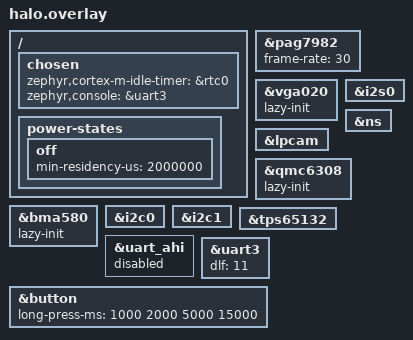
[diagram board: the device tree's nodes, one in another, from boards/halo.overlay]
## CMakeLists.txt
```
# SPDX-License-Identifier: Apache-2.0
cmake_minimum_required(VERSION 3.20.0)

# Handle RELEASE build option
# Default is debug build
# Use environment variable: RELEASE=1 west build ... for release build
set(RELEASE OFF CACHE BOOL "Enable release build")

# Check environment variable first (works with sysbuild)
if(DEFINED ENV{RELEASE} AND "$ENV{RELEASE}" STREQUAL "1")
    set(RELEASE ON)
endif()

if(RELEASE)
    message(STATUS "=== Release build enabled ===")
    set(EXTRA_CONF_FILE "release.conf" CACHE STRING "Extra config file" FORCE)
    set(BUILD_EXTRAVERSION "")
else()
    message(STATUS "=== Debug build enabled (default) ===")
    set(EXTRA_CONF_FILE "debug.conf" CACHE STRING "Extra config file" FORCE)
    set(BUILD_EXTRAVERSION "debug")
endif()

# DIAG=1: the bring-up experiment build (diag.conf: /lfs/diag.txt event log and
# the staged boot). Tagged in the version string so it can't pass for a release.
if(DEFINED ENV{DIAG} AND "$ENV{DIAG}" STREQUAL "1")
    message(STATUS "=== Diagnostic (staged boot) build ===")
    set(EXTRA_CONF_FILE "${EXTRA_CONF_FILE};diag.conf" CACHE STRING "Extra config file" FORCE)
    if(BUILD_EXTRAVERSION STREQUAL "")
        set(BUILD_EXTRAVERSION "diag")
    else()
        set(BUILD_EXTRAVERSION "${BUILD_EXTRAVERSION}diag")
    endif()
endif()

# Update VERSION file with correct EXTRAVERSION
file(READ "${CMAKE_CURRENT_SOURCE_DIR}/VERSION" VERSION_CONTENT)
string(REGEX REPLACE "EXTRAVERSION = [^\n]*" "EXTRAVERSION = ${BUILD_EXTRAVERSION}" VERSION_CONTENT "${VERSION_CONTENT}")
file(WRITE "${CMAKE_CURRENT_SOURCE_DIR}/VERSION" "${VERSION_CONTENT}")

if(SYSBUILD)
    list(APPEND EXTRA_CONF_FILE "prj_sysbuild.conf")
endif()

find_package(Zephyr REQUIRED HINTS $ENV{ZEPHYR_BASE})

project(halo)

include_directories("include")

file(GLOB_RECURSE SRC_FILES "src/*.c")
target_sources(app PRIVATE ${SRC_FILES})

libmpix_init(app)
```

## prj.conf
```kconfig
# Zephyr Project Configuration File

# Zephyr Base Configuration
CONFIG_ASSERT=y
CONFIG_LOG=y
CONFIG_LOG_DEFAULT_LEVEL=2
CONFIG_LOG_BUFFER_SIZE=8192
CONFIG_LOG_PROCESS_THREAD_CUSTOM_PRIORITY=y
CONFIG_LOG_PROCESS_THREAD_PRIORITY=3
CONFIG_LOG_PROCESS_THREAD_STACK_SIZE=2048

# Log Filesystem Backend — persist logs to LittleFS. DISABLED on this
# branch: littlefs writes hit the same flash the code executes from, so
# every persisted log line (e.g. the AEC's 10-s load INF) stalls the
# whole system mid-audio-session — the same mechanism as the /lfs
# capture-write emission gaps the AEC harnesses had to design around.
# Also returns the 2x16KB log files to /lfs. Re-enable when the audio
# timing work no longer needs stall-free sessions (the `logs` skill
# depends on it for post-flash diagnostics; `verify.py` still covers
# boot checks).
CONFIG_LOG_BACKEND_FS=n
# CONFIG_LOG_BACKEND_FS_DIR="/lfs"
# CONFIG_LOG_BACKEND_FS_AUTOSTART=y
# CONFIG_LOG_BACKEND_FS_OVERWRITE=y
# CONFIG_LOG_BACKEND_FS_FILE_PREFIX="log."
# CONFIG_LOG_BACKEND_FS_FILE_SIZE=16384
# CONFIG_LOG_BACKEND_FS_FILES_LIMIT=2

# System Workqueue Configuration
CONFIG_MAIN_STACK_SIZE=4096
CONFIG_ISR_STACK_SIZE=4096
CONFIG_PRIVILEGED_STACK_SIZE=2048
CONFIG_IDLE_STACK_SIZE=2048
CONFIG_SYSTEM_WORKQUEUE_STACK_SIZE=4096

# Power Management Configuration
CONFIG_PM=y
CONFIG_PM_DEVICE=y

# Thread Monitoring and Debugging
CONFIG_THREAD_NAME=y
CONFIG_THREAD_MONITOR=y
CONFIG_THREAD_STACK_INFO=y
CONFIG_THREAD_RUNTIME_STATS=y

# Round-robin equal-priority threads at priority 7 and below in 5 ms slices.
# The Lua REPL and the camera capture thread share priority 7: without
# slicing, a capture's ~0.5 s debayer/JPEG pass held the CPU and froze the
# Lua loop (stalling e.g. the mic stream it sends) until the image was ready.
CONFIG_TIMESLICE_SIZE=5
CONFIG_TIMESLICE_PRIORITY=7


# Halo Framework
CONFIG_HALO=y
# Acoustic echo cancellation (speaker leakage removed from the mic path)
CONFIG_HALO_AUDIO_AEC=y
CONFIG_HALO_AUDIO_AEC_TAPS=1024
CONFIG_MPIX_LOG_LEVEL_WRN=y
CONFIG_FS_LOG_LEVEL_WRN=y

# Memory Manager Configuration
# The libc malloc arena defaults to "all RAM left after static allocations",
# which had decayed to ~50 bytes - any .bss growth then fails the sys_heap
# minimum-size assert in malloc_prepare() and the image panics at boot.
# Pin the arena explicitly and give back one page from the internal pool so
# the link keeps real headroom.
CONFIG_COMMON_LIBC_MALLOC_ARENA_SIZE=2048
# (also funds the AEC's 256ms reference ring and its ~3.3KB paired-capture
# snapshot buffers - see audio_aec.c)
CONFIG_HALO_MEM_INTERNAL_SIZE=352256
CONFIG_HALO_MEM_USE_EXTERNAL_SRAM=y
CONFIG_HALO_MEM_EXTERNAL_SRAM_ADDR=0x00000000
# The first 64KB of ITCM belong to the AEC FDAF state (the linker's ITCM
# section; BUILD_ASSERTed in audio_aec.c to fit below this offset) - the
# region-1 heap starts above it. Was offset 4096 (NULL guard) + 520192.
CONFIG_HALO_MEM_EXTERNAL_SRAM_OFFSET=65536
CONFIG_HALO_MEM_EXTERNAL_SRAM_SIZE=458752
CONFIG_HALO_MEM_MANAGER_STATS=y

# Flash and Storage Configuration
CONFIG_FLASH=y
CONFIG_FLASH_MAP=y
CONFIG_FLASH_PAGE_LAYOUT=y
CONFIG_MPU_ALLOW_FLASH_WRITE=y

# LittleFS Configuration
CONFIG_FILE_SYSTEM_LITTLEFS=y
CONFIG_FS_LITTLEFS_FMP_DEV=y

# Settings Configuration
CONFIG_SETTINGS=y
CONFIG_SETTINGS_FILE=y
CONFIG_SETTINGS_FILE_PATH="/lfs/settings"

# Sensor Configuration for Battery Service
CONFIG_SENSOR=y
CONFIG_SENSOR_INIT_PRIORITY=60

# Regulator Init Priority
# cam_1v8 (regulator-fixed, priority 32) must initialize before tps65132
# (REGULATOR_TPS65132_COMMON_INIT_PRIORITY=61), since tps65132 has
# vin-supply = <&cam_1v8> and checks device_is_ready() during init.
CONFIG_REGULATOR_FIXED_INIT_PRIORITY=32
# The camera reset release (camera_boot.c, 60) sits between the camera
# driver (VIDEO_INIT_PRIORITY) and the tps65132 regulator (61), so the
# camera driver moves one ahead.
CONFIG_VIDEO_INIT_PRIORITY=59
# The camera controller's pin control muxes the sensor clock pad; it must run
# before the reset release switches that clock on.
CONFIG_VIDEO_ALIF_CAM_INIT_PRIORITY=59

# LED Configuration for Battery Charging Indicator
CONFIG_PWM=y
CONFIG_LED_PWM=y

# Halo BLE Manager Configuration
CONFIG_HALO_BLE_MAX_SERVICES=8
CONFIG_HALO_BLE_BOND_STORAGE=y
CONFIG_HALO_BLE_REQUIRE_PAIRING=y
CONFIG_HALO_BLE_ALLOW_BOND_OVERWRITE=n


# BLE Lua Service Configuration
CONFIG_HALO_BLE_LUA_SERVICE=y
CONFIG_HALO_LUA_MAX_REPL_SIZE=1024
CONFIG_HALO_LUA_MAX_DATA_SIZE=4096
CONFIG_HALO_AUDIO_MAX_DATA_SIZE=8192
CONFIG_HALO_SFXR=y
CONFIG_HALO_LUA_SOUND=y
CONFIG_HALO_STARTUP_SOUND=y
CONFIG_HALO_STARTUP_SOUND_PRESET="powerup"
CONFIG_HALO_STARTUP_SOUND_SEED=4149902225
CONFIG_HALO_STARTUP_SOUND_DURATION_MS=1000
# Boot/shutdown cues play at the app-wide SFXR level (20).
CONFIG_HALO_STARTUP_SOUND_VOLUME=20
CONFIG_HALO_SHUTDOWN_SOUND=y
CONFIG_HALO_SHUTDOWN_SOUND_PRESET="laser"
CONFIG_HALO_SHUTDOWN_SOUND_SEED=573636714
CONFIG_HALO_SHUTDOWN_SOUND_DURATION_MS=700
CONFIG_HALO_SHUTDOWN_SOUND_VOLUME=20

# Boot logo splash (drawn pre-runtime_init, held for the startup sound duration)
CONFIG_HALO_BOOT_LOGO=y

# Lua Runtime Configuration
CONFIG_HALO_LUA_RUNTIME=y
# REPL thread: 128KB stack for Lua VM and complex user scripts
CONFIG_HALO_LUA_REPL_TASK_STACK_SIZE=65536
CONFIG_HALO_LUA_REPL_TASK_PRIORITY=7

# Watchdog Configuration
CONFIG_HALO_WATCHDOG_MANAGER=y
CONFIG_HALO_WATCHDOG_TIMEOUT_MS=5000
CONFIG_HALO_WATCHDOG_ALLOW_CALLBACK=y
CONFIG_HALO_WATCHDOG_AUTO_FEED=y
CONFIG_HALO_WATCHDOG_AUTO_FEED_PRIORITY=2
CONFIG_HALO_WATCHDOG_AUTO_FEED_STACK_SIZE=2048
CONFIG_HALO_WATCHDOG_FEED_INTERVAL_MS=1000

CONFIG_HALO_BLE_MANAGER=y

CONFIG_HALO_SE_MGMT=y

CONFIG_BOOT_BANNER=n


CONFIG_HALO_BATTERY_MANAGER=y
CONFIG_HALO_LED_MANAGER=y
CONFIG_HALO_WATCHDOG_MANAGER=y
CONFIG_HALO_LUA_RUNTIME=y
CONFIG_HALO_BLE_ALLOW_BOND_OVERWRITE=n

CONFIG_HALO_BLE_AUDIO_SERVICE=y
CONFIG_HALO_BLE_AUDIO_SINK_ENABLE=y
CONFIG_HALO_BLE_AUDIO_OUTPUT_STEREO=y
CONFIG_HALO_BLE_AUDIO_SOURCE_ENABLE=y
CONFIG_HALO_BLE_AUDIO_INPUT_STEREO=n

# Set a current budget for the speakers to avoid tripping the battery protection IC
CONFIG_MAX98357A_AUDIO_PROTECT_BUDGET_PERCENT=80
```

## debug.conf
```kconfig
# Debug build configuration
CONFIG_HALO_LOG_LEVEL_DBG=y
```

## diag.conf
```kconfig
# Bring-up experiment build (DIAG=1): event log in /lfs/diag.txt and the
# staged boot. Settings in /lfs/diag.cfg; see HALO_SLOW_BOOT in modules/halo/Kconfig.
CONFIG_HALO_DIAG_LOG=y
CONFIG_HALO_SLOW_BOOT=y
```

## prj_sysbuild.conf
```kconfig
#OTA
CONFIG_NET_BUF=y
CONFIG_ZCBOR=y
CONFIG_MCUMGR=y
CONFIG_STREAM_FLASH=y
CONFIG_FLASH_MAP=y
CONFIG_BOOTLOADER_MCUBOOT=y
CONFIG_FLASH=y
CONFIG_IMG_MANAGER=y
CONFIG_MCUMGR_GRP_IMG=y
CONFIG_MCUMGR_GRP_OS=y
# Let ble_ota force a cold BLE start before an mcumgr "os reset"
CONFIG_MCUMGR_GRP_OS_RESET_HOOK=y
CONFIG_MCUMGR_TRANSPORT_NETBUF_SIZE=517
# DFU status hooks: lets the app log OTA start/finish/failure (see ble_ota.c)
CONFIG_MCUMGR_MGMT_NOTIFICATION_HOOKS=y
CONFIG_MCUMGR_GRP_IMG_STATUS_HOOKS=y
CONFIG_INIT_ARCH_HW_AT_BOOT=n
```

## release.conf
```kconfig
# Release build configuration
CONFIG_HALO_LOG_LEVEL_INF=y
```

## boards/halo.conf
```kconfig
# FLASH 
CONFIG_FLASH=y
CONFIG_FLASH_MAP=y
CONFIG_FLASH_PAGE_LAYOUT=y
CONFIG_MPU_ALLOW_FLASH_WRITE=y

CONFIG_RESET=y
CONFIG_I2C=y
CONFIG_I2C_DW=y
CONFIG_I2C_DW_CLOCK_SPEED=40
# Counter
CONFIG_COUNTER=y
CONFIG_COUNTER_RTC_SNPS_DW=y
CONFIG_COUNTER_SNPS_DW=y


# BLE 
CONFIG_BT=y
CONFIG_BT_CUSTOM=y
CONFIG_ALIF_BLE_HOST_THREAD_PRIORITY=1
CONFIG_ALIF_BLE_HOST_THREAD_STACKSIZE=10240
CONFIG_ALIF_BLE_HOST_ADDL_PRF_HEAPSIZE=10240
CONFIG_ALIF_BLE_HOST_ADDL_ENV_HEAPSIZE=8192

# Display
CONFIG_DISPLAY=y
CONFIG_CDC200=y
CONFIG_MIPI_DSI=y
CONFIG_CANVAS=y
CONFIG_FB_USES_DTCM_REGION=y

# Sensors
CONFIG_BMA580_TRIGGER_OWN_THREAD=y

# Camera
CONFIG_VIDEO=y
CONFIG_VIDEO_MIPI_CSI2_DW=n
CONFIG_VIDEO_BUFFER_POOL_NUM_MAX=1
CONFIG_VIDEO_BUFFER_POOL_SZ_MAX=327680
CONFIG_FB_USES_DTCM_REGION=y
CONFIG_MPIX=y
CONFIG_MPIX_HEAP_SIZE=81920

#Audio
CONFIG_AUDIO=y
CONFIG_I2S=y
CONFIG_MAX98357A_AUDIO=y
CONFIG_MAX98357A_AUDIO_GENERIC_API=y
CONFIG_MAX98357A_AUDIO_SYNC_BLOCK_SIZE=640
CONFIG_MAX98357A_AUDIO_SYNC_BLOCK_COUNT=8
CONFIG_AUDIO_DMIC=y
CONFIG_ALIF_BLE_AUDIO=n
CONFIG_ALIF_ROM_LC3_CODEC=y
CONFIG_T5838_AAD_TRIGGER_OWN_THREAD=y

CONFIG_SOC_B1_DCDC_VOLTAGE=775
CONFIG_SE_SERVICE_INIT_PRIORITY=1
CONFIG_KERNEL_INIT_PRIORITY_DEFAULT=0
CONFIG_GPIO_INIT_PRIORITY=40

CONFIG_ALIF_MAX_SLEEP_CLOCK_DRIFT=252
CONFIG_ALIF_MAX_ACTIVE_CLOCK_DRIFT=252

CONFIG_CORTEX_M_SYSTICK_IDLE_TIMER=y

CONFIG_SYS_CLOCK_TICKS_PER_SEC=1000

CONFIG_SERIAL_INIT_PRIORITY=40
CONFIG_CONSOLE_INIT_PRIORITY=42
```

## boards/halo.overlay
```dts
&pag7982{
	status = "okay";
	frame-rate = <30>;
};

&vga020 {
	lazy-init;
};

&i2s0 {
	status = "okay";
};

&lpcam {
	status = "okay";
};

ns: &ns {
	status = "okay";
};

&qmc6308{
	status = "okay";
	lazy-init;
};

&bma580{
	status = "okay";
	lazy-init;
};

&i2c0 {
	status = "okay";
};
&i2c1 {
	status = "okay";
};
&tps65132 {
	status = "okay";
};

&uart_ahi {
	status = "disabled";
};

/*
 * The console runs from SYST_PCLK, which the SoC dtsi already declares as
 * 40 MHz — so no clock-frequency override here (the old 38400000 existed
 * only for the HFOSC switch that power_mgr.c used to do; see #249).
 *
 * 40 MHz / (16 * 115200) = 21.70. The driver truncates that to a divisor of
 * 21 (119047 baud, +3.3%), so pair it with the fractional divisor DLF =
 * 11/16 to get 21.6875 -> 115273 baud, 0.06% off.
 */
&uart3 {
	dlf = < 11 >;
	status = "okay";
};
/ {
	chosen {
		zephyr,cortex-m-idle-timer = &rtc0;
		zephyr,console = &uart3;
	};

	power-states {
		off: off {
			/* 2s is time reserved for os wakeup and sleep */
			min-residency-us = < 2000000 >;
		};
	};
};

/* Modify the existing button to add 4th level (15s for shutdown) */
&button {
	/* 1s (release), 3s (release), 8s (auto), 15s (auto) */
	long-press-ms = <1000 2000 5000 15000>;
};
```

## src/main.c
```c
/*
 * Copyright (c) 2025 Brilliant Labs Inc.
 * SPDX-License-Identifier: Apache-2.0
 */

#include <zephyr/kernel.h>
#include <zephyr/logging/log.h>
#include <zephyr/logging/log_ctrl.h>
#include <zephyr/sys/printk.h>
#include <zephyr/sys/reboot.h>
#include <zephyr/drivers/sensor.h>
#include <app_version.h>

#include <halo/mem_manager.h>
#include <halo/file_manager.h>
#ifdef CONFIG_HALO_AUDIO_STREAM
#include <halo/audio_stream.h>
#endif
#include <halo/pm_manager.h>
#include <halo/led_manager.h>

#include <zephyr/drivers/input/button.h>

#ifdef CONFIG_SENSOR
#include <halo/battery_manager.h>
#endif

#ifdef CONFIG_HALO_BLE_MANAGER
#include <halo/ble_manager.h>
#include <halo/ble_connection.h>
#include <halo/ble_security.h>
#ifdef CONFIG_HALO_BLE_LUA_SERVICE
#include <halo/ble_lua.h>
#endif
#endif

#ifdef CONFIG_HALO_LUA_RUNTIME
#include <halo/lua_runtime.h>
#endif

#if defined(CONFIG_HALO_STARTUP_SOUND) || defined(CONFIG_HALO_SHUTDOWN_SOUND)
#include <halo/sfxr.h>
#endif

#ifdef CONFIG_HALO_BOOT_LOGO
#include <halo/boot_logo.h>
#endif

#ifdef CONFIG_HALO_WATCHDOG_MANAGER
#include <halo/watchdog_manager.h>
#endif

#include <zephyr/drivers/regulator.h>
#include <zephyr/pm/device.h>

#if defined(CONFIG_BOOTLOADER_MCUBOOT) && defined(CONFIG_MCUBOOT_IMG_MANAGER)
#include <zephyr/dfu/mcuboot.h>
#endif

#include "se_service.h"

LOG_MODULE_REGISTER(halo, CONFIG_HALO_LOG_LEVEL);

const char halo_banner[] = "    _    _       _       \n"
			   "   | |  | |     | |      \n"
			   "   | |__| | __ _| | ___  \n"
			   "   |  __  |/ _` | |/ _ \\ \n"
			   "   | |  | | (_| | | (_) |\n"
			   "   |_|  |_|\\__,_|_|\\___/ \n"
			   "   Copyright (C) 2025 Brilliant Labs\n"
			   "   https://brilliant.xyz/\n";

/**
 * @brief Main application entry point
 *
 * Initializes all core subsystems and starts the Lua runtime.
 * The system is then driven by Lua scripts and BLE events.
 */
int main(void)
{
	int ret;

#ifdef CONFIG_HALO_WATCHDOG_MANAGER
	if (halo_watchdog_has_fired()) {
		// Reboot on watchdog timeout, make sure everything is fresh
#ifdef CONFIG_HALO_PM_MANAGER
		halo_pm_report_interrupted_entry(true);
		log_panic();
#endif
#ifdef CONFIG_HALO_BLE_MANAGER
		halo_ble_conn_prepare_reboot();
#endif
		sys_reboot(SYS_REBOOT_COLD);
	}
#endif
#ifdef CONFIG_HALO_PM_MANAGER
	halo_pm_report_interrupted_entry(false);
#endif
#ifdef CONFIG_HALO_LOG_LEVEL_DBG
	printk("\n%s", halo_banner);
	printk("Hardware Version: %s\n", CONFIG_BOARD);
	printk("Firmware Version: %s\n", APP_VERSION_STRING);
	printk("Build Date: %s\n", __DATE__);
#endif

#ifdef CONFIG_HALO_PM_MANAGER
	/* Initialize power manager */
	ret = halo_pm_init();
	if (ret < 0) {
		__ASSERT(false, "Failed to initialize power manager: %d", ret);
		return ret;
	}
#endif

#ifdef CONFIG_HALO_MEM_MANAGER
	/* Initialize memory manager */
	ret = halo_mem_init();
	if (ret < 0) {
		__ASSERT(false, "Failed to initialize memory manager: %d", ret);
		return ret;
	}
#endif

#ifdef CONFIG_HALO_WATCHDOG_MANAGER
	/* Initialize watchdog manager */
	ret = halo_watchdog_init();
	if (ret < 0) {
		__ASSERT(false, "Failed to initialize watchdog manager: %d", ret);
		return ret;
	}
#endif

#ifdef CONFIG_HALO_LED_MANAGER
	/* Initialize LED manager */
	ret = halo_led_init();
	if (ret < 0) {
		__ASSERT(false, "Failed to initialize LED manager: %d", ret);
		return ret;
	}
#endif

#ifdef CONFIG_HALO_BATTERY_MANAGER
	/* Initialize battery manager */
	ret = halo_battery_init();
	if (ret < 0) {
		__ASSERT(false, "Failed to initialize battery manager: %d", ret);
		return ret;
	}
#endif

#ifdef CONFIG_HALO_FILE_MANAGER
	/* Initialize file manager */
	ret = halo_file_init();
	if (ret < 0) {
		__ASSERT(false, "Failed to initialize file manager: %d", ret);
		return ret;
	}
#ifdef CONFIG_HALO_AUDIO_STREAM
	/* Before the startup sound, so it plays with this unit's polarity */
	(void)audio_speaker_polarity_load();
#endif
#endif

#ifdef CONFIG_HALO_BLE_MANAGER
	/* Initialize BLE manager */
	ret = halo_ble_init(NULL);
	if (ret < 0) {
		__ASSERT(false, "Failed to initialize BLE manager: %d", ret);
		return ret;
	}

#endif /* CONFIG_HALO_BLE_MANAGER */

#if defined(CONFIG_HALO_STARTUP_SOUND) || defined(CONFIG_HALO_BOOT_LOGO)
	/*
	 * Boot splash: kick off the (async) startup sound and draw the logo
	 * BEFORE the Lua runtime starts. main.lua runs on the REPL thread as
	 * soon as halo_lua_runtime_init() is called and would clear the display
	 * out from under the logo. Holding here on the main thread (which only
	 * sleeps forever afterwards) keeps the splash up with no race against
	 * the app: we wait for the sound to finish (when enabled), then top up
	 * to a minimum hold time. An unpaired device holds longer and shows its
	 * BLE name under the logo so the user can identify it while pairing.
	 *
	 * The sound wait and the minimum hold do not depend on the logo: when
	 * the display cannot show the splash, boot still sounds and still takes
	 * the same time, so the app starts at the same moment on every boot and
	 * cannot claim the speaker out from under the startup cue. Only the
	 * longer unpaired hold needs the logo up, since its purpose is the name.
	 */
#ifdef CONFIG_HALO_STARTUP_SOUND
	halo_startup_sound_schedule();
#endif
	int64_t splash_start = k_uptime_get();
	int64_t hold_ms = 0;
	bool splash_shown = false;

#ifdef CONFIG_HALO_BOOT_LOGO
	bool splash_unpaired = false;
	const char *splash_label = NULL;
#ifdef CONFIG_HALO_BLE_MANAGER
	splash_unpaired = !halo_ble_sec_is_bonded();
	if (splash_unpaired) {
		splash_label = halo_ble_conn_get_device_name();
	}
#endif
	splash_shown = (halo_display_boot_logo_show(splash_label) == 0);
	hold_ms = (splash_shown && splash_unpaired) ? CONFIG_HALO_BOOT_LOGO_UNPAIRED_HOLD_MS
						   : CONFIG_HALO_BOOT_LOGO_MIN_HOLD_MS;
#endif
#ifdef CONFIG_HALO_STARTUP_SOUND
	/* Bounded so a missing/stuck speaker can't stall boot. */
	halo_startup_sound_wait(CONFIG_HALO_STARTUP_SOUND_TIMEOUT_MS +
				CONFIG_HALO_STARTUP_SOUND_DURATION_MS + 250);
#endif
	int64_t remaining_ms = hold_ms - (k_uptime_get() - splash_start);

	if (remaining_ms > 0) {
		k_sleep(K_MSEC(remaining_ms));
	}
#ifdef CONFIG_HALO_BOOT_LOGO
	if (splash_shown) {
		halo_display_boot_logo_hide();
	}
#endif
#endif

#ifdef CONFIG_HALO_LUA_RUNTIME
	/* Initialize Lua runtime - this is the core of the system */
	ret = halo_lua_runtime_init();
	if (ret < 0) {
		__ASSERT(false, "Failed to initialize Lua runtime: %d", ret);
		return ret;
	}
#endif

#if defined(CONFIG_BOOTLOADER_MCUBOOT) && defined(CONFIG_MCUBOOT_IMG_MANAGER)
	/*
	 * Mark this image as confirmed now that the full boot sequence has
	 * succeeded. This must be the last step of bring-up: if any subsystem
	 * above hangs or faults, the image stays unconfirmed and MCUboot reverts
	 * to the previously good image on the next reset (the app-level watchdog
	 * provides that reset). Confirming earlier would defeat that safety net.
	 * boot_write_img_confirmed() is a no-op when the image is already confirmed.
	 */
	ret = boot_write_img_confirmed();
	if (ret < 0) {
		LOG_ERR("Failed to confirm MCUboot image: %d", ret);
	} else {
		LOG_INF("MCUboot image confirmed");
	}
#endif

#if defined(CONFIG_HALO_STARTUP_SOUND) || defined(CONFIG_HALO_SHUTDOWN_SOUND)
	/* Boot settled: re-arm the boot/shutdown cues for the next power-on.
	 * Must stay after the image confirm so a boot that ends earlier keeps
	 * the cue gate flag set (see CONFIG_HALO_CUE_GATE_DIRTY_BOOT). */
	halo_sound_cue_boot_settled();
#endif

	while (1) {
		k_sleep(K_FOREVER);
	}

	return 0;
}
```
